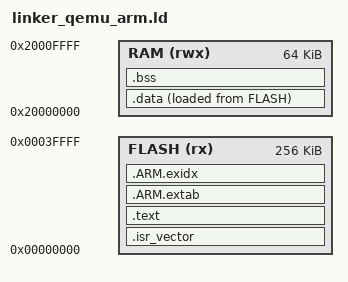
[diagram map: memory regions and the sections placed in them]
/*
 * This file is part of mipOS
 * Copyright (c) Antonino Calderone (antonino.calderone@gmail.com)
 * Licensed under the MIT License.
 *
 * Linker script for the QEMU lm3s6965evb board (TI Stellaris LM3S6965):
 *   flash: 256 KiB @ 0x00000000
 *   sram :  64 KiB @ 0x20000000
 */

ENTRY(Reset_Handler)

MEMORY
{
    FLASH (rx)  : ORIGIN = 0x00000000, LENGTH = 256K
    RAM   (rwx) : ORIGIN = 0x20000000, LENGTH = 64K
}

/* Initial stack pointer: top of RAM */
_estack = ORIGIN(RAM) + LENGTH(RAM);

SECTIONS
{
    .isr_vector :
    {
        . = ALIGN(4);
        KEEP(*(.isr_vector))
        . = ALIGN(4);
    } > FLASH

    .text :
    {
        . = ALIGN(4);
        *(.text*)
        *(.rodata*)
        . = ALIGN(4);
    } > FLASH

    .ARM.extab :
    {
        *(.ARM.extab* .gnu.linkonce.armextab.*)
    } > FLASH

    .ARM.exidx :
    {
        __exidx_start = .;
        *(.ARM.exidx* .gnu.linkonce.armexidx.*)
        __exidx_end = .;
    } > FLASH

    /* Load address of .data in flash, used by the startup code */
    _sidata = LOADADDR(.data);

    .data :
    {
        . = ALIGN(4);
        _sdata = .;
        *(.data*)
        . = ALIGN(4);
        _edata = .;
    } > RAM AT> FLASH

    .bss (NOLOAD) :
    {
        . = ALIGN(4);
        _sbss = .;
        *(.bss*)
        *(COMMON)
        . = ALIGN(4);
        _ebss = .;
    } > RAM

    /* Heap start for the (unused) newlib sbrk stub */
    PROVIDE(end = _ebss);
    PROVIDE(_end = _ebss);

    /DISCARD/ :
    {
        *(.init) *(.fini)
        *(.init_array*) *(.fini_array*)
    }
}
